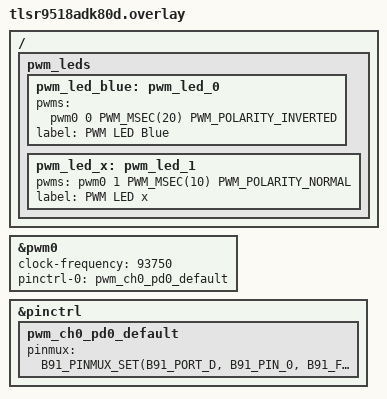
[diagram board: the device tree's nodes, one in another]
/ {
	pwm_leds {
		pwm_led_blue: pwm_led_0 {
			pwms = <&pwm0 0 PWM_MSEC(20) PWM_POLARITY_INVERTED>;
			label = "PWM LED Blue";
		};
		pwm_led_x: pwm_led_1 {
			pwms = <&pwm0 1 PWM_MSEC(10) PWM_POLARITY_NORMAL>;
			label = "PWM LED x";
		};
	};
};

&pwm0 {
	status = "okay";
	clock-frequency = <93750>;
	pinctrl-0 = <&pwm_ch0_pd0_default>;
	pinctrl-names = "default";
};

&pinctrl {
	pwm_ch0_pd0_default: pwm_ch0_pd0_default {
		pinmux = <B91_PINMUX_SET(B91_PORT_D, B91_PIN_0, B91_FUNC_C)>;
	};
};
